# generated register map
File version: 1.0
Registers are 32-bit, access not given, no defined reset value unless marked. A register's access mark holds for its fields unless they carry their own. Offsets are from the block's base; lines under a group give offsets from that group; [hi:lo] are bit positions; {n}, {i} and the like mark numbered series; 'fields as' and 'values as' point back to an identical list; <NAME> marks a mode.

## Memory map
0x60044000 etm
0x60047000 ieee802154
0x60049000 coex
0x6004B000 clkrst

## coex
Base 0x60049000
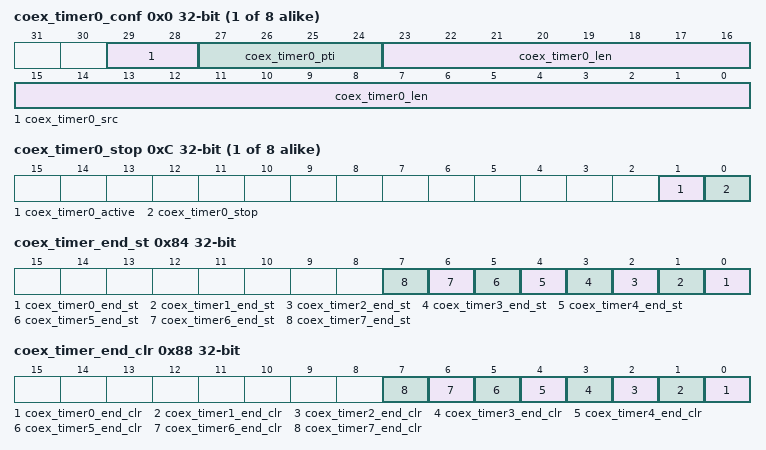
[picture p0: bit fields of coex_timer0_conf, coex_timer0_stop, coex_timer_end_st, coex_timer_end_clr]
{0x0+0x10*i} coex_timer{i}_conf (i=0..7)
  [29:28] coex_timer{i}_src, [27:24] coex_timer{i}_pti, [23:0] coex_timer{i}_len
{0x4+0x10*i} coex_timer{i}_conf1 (i=0..7)
  [23:0] coex_timer{i}_begin
{0x8+0x10*i} coex_timer{i}_start (i=0..7)
  [0] coex_timer{i}_start
{0xC+0x10*i} coex_timer{i}_stop (i=0..7)
  [1] coex_timer{i}_active, [0] coex_timer{i}_stop
0x80 coex_timer
  [23:0] coex_ctimer
0x84 coex_timer_end_st
  [n] coex_timer{n}_end_st (n=0..7)
0x88 coex_timer_end_clr
  [n] coex_timer{n}_end_clr (n=0..7)
0x8C coex_int_ena
  [0] coex_timer_end_int_ena
0x90 coex_int_raw
  [0] coex_timer_end_int_raw
0x94 coex_int_st
  [0] coex_timer_end_int_st
0x98 coex_int_clr
  [0] coex_timer_end_int_clr
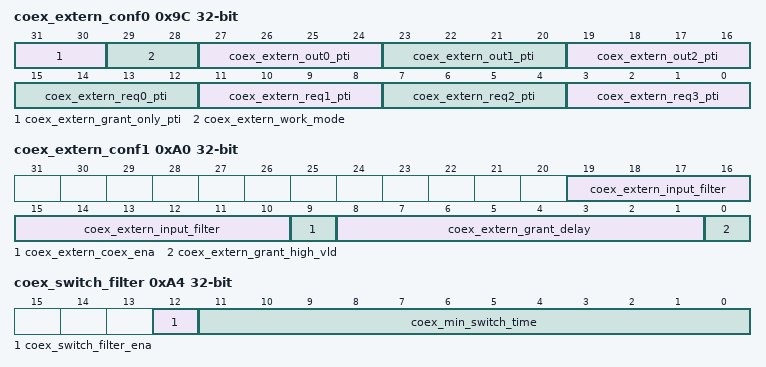
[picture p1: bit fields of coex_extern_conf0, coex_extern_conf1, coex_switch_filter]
0x9C coex_extern_conf0
  [31:30] coex_extern_grant_only_pti, [29:28] coex_extern_work_mode, [27:24] coex_extern_out0_pti, [23:20] coex_extern_out1_pti, [19:16] coex_extern_out2_pti, [15-4n:12-4n] coex_extern_req{n}_pti (n=0..3)
0xA0 coex_extern_conf1
  [19:10] coex_extern_input_filter, [9] coex_extern_coex_ena, [8:1] coex_extern_grant_delay, [0] coex_extern_grant_high_vld
0xA4 coex_switch_filter
  [12] coex_switch_filter_ena, [11:0] coex_min_switch_time
0xA8 coex_clk_conf
  [0] coex_clk_en
{0xAC+4i} coex_src{i}_disbale (i=0..2)
  [0] coex_src{i}_dis
{0xB8+4i} ocex_src{i}_select (i=0..2)
  [1:0] coex_src{i}_sel
0xC4 coex_date
  [27:0] coex_date

## etm
Base 0x60044000
0x00 etm_chen_ad0
0x04 etm_chenset_ad0
0x08 etm_chenclr_ad0
0x18 etm_ch0_evt_id
0x1C etm_ch0_task_id
0xDC etm_clk_en

## clkrst
Base 0x6004B000
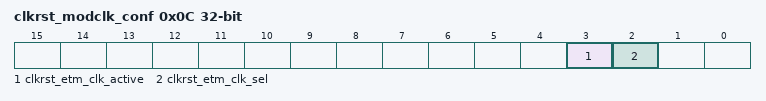
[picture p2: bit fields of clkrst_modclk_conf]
0x0C clkrst_modclk_conf
  [3] clkrst_etm_clk_active, [2] clkrst_etm_clk_sel
